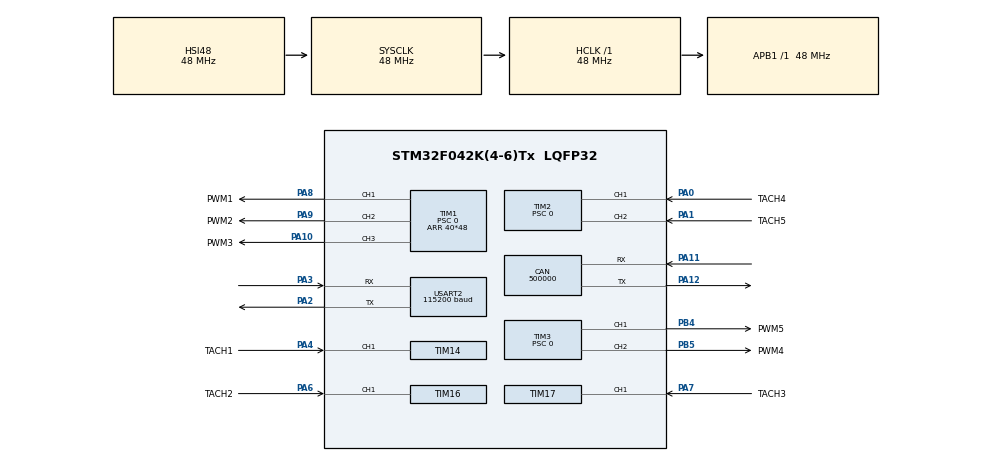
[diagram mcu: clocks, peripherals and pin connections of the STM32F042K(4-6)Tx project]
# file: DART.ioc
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CAN.BS1=CAN_BS1_4TQ
CAN.CalculateBaudRate=500000
CAN.CalculateTimeBit=2000
CAN.CalculateTimeQuantum=333.3333333333333
Dma.Request0=USART2_RX
Dma.Request1=USART2_TX
Dma.USART2_RX.0.Direction=DMA_PERIPH_TO_MEMORY
Dma.USART2_RX.0.Instance=DMA1_Channel5
Dma.USART2_RX.0.MemDataAlignment=DMA_MDATAALIGN_BYTE
Dma.USART2_RX.0.MemInc=DMA_MINC_ENABLE
Dma.USART2_RX.0.Mode=DMA_CIRCULAR
Dma.USART2_RX.0.PeriphDataAlignment=DMA_PDATAALIGN_BYTE
Dma.USART2_RX.0.PeriphInc=DMA_PINC_DISABLE
Dma.USART2_RX.0.Priority=DMA_PRIORITY_LOW
Dma.USART2_TX.1.Direction=DMA_MEMORY_TO_PERIPH
Dma.USART2_TX.1.Instance=DMA1_Channel4
Dma.USART2_TX.1.MemDataAlignment=DMA_MDATAALIGN_BYTE
Dma.USART2_TX.1.MemInc=DMA_MINC_ENABLE
Dma.USART2_TX.1.Mode=DMA_NORMAL
Dma.USART2_TX.1.PeriphDataAlignment=DMA_PDATAALIGN_BYTE
Dma.USART2_TX.1.PeriphInc=DMA_PINC_DISABLE
Dma.USART2_TX.1.Priority=DMA_PRIORITY_LOW
Mcu.Family=STM32F0
Mcu.Name=STM32F042K(4-6)Tx
Mcu.Package=LQFP32
NVIC.CEC_CAN_IRQn=true\:0\:0\:false\:false\:true\:true\:true\:true
NVIC.DMA1_Channel4_5_IRQn=true\:0\:0\:false\:false\:true\:false\:true\:true
NVIC.TIM14_IRQn=true\:0\:0\:false\:false\:true\:true\:true\:true
NVIC.TIM16_IRQn=true\:0\:0\:false\:false\:true\:true\:true\:true
NVIC.TIM17_IRQn=true\:0\:0\:false\:false\:true\:true\:true\:true
NVIC.TIM1_BRK_UP_TRG_COM_IRQn=true\:0\:0\:false\:false\:true\:true\:true\:true
NVIC.TIM1_CC_IRQn=true\:0\:0\:false\:false\:true\:true\:true\:true
NVIC.TIM2_IRQn=true\:0\:0\:false\:false\:true\:true\:true\:true
NVIC.TIM3_IRQn=true\:0\:0\:false\:false\:true\:true\:true\:true
NVIC.USART2_IRQn=true\:0\:0\:false\:false\:true\:true\:true\:true
PA0.GPIO_Label=TACH4
PA0.Signal=S_TIM2_CH1_ETR
PA1.GPIO_Label=TACH5
PA1.Signal=S_TIM2_CH2
PA10.GPIO_Label=PWM3
PA10.Signal=S_TIM1_CH3
PA11.Mode=CAN_Activate
PA11.Signal=CAN_RX
PA12.Mode=CAN_Activate
PA12.Signal=CAN_TX
PA13.Mode=Serial_Wire
PA13.Signal=SYS_SWDIO
PA14.Mode=Serial_Wire
PA14.Signal=SYS_SWCLK
PA2.Mode=Asynchronous
PA2.Signal=USART2_TX
PA3.Mode=Asynchronous
PA3.Signal=USART2_RX
PA4.GPIO_Label=TACH1
PA4.Signal=S_TIM14_CH1
PA6.GPIO_Label=TACH2
PA6.Signal=S_TIM16_CH1
PA7.GPIO_Label=TACH3
PA7.Signal=S_TIM17_CH1
PA8.GPIO_Label=PWM1
PA8.Signal=S_TIM1_CH1
PA9.GPIO_Label=PWM2
PA9.Signal=S_TIM1_CH2
PB4.GPIO_Label=PWM5
PB4.Signal=S_TIM3_CH1
PB5.GPIO_Label=PWM4
PB5.Signal=S_TIM3_CH2
ProjectManager.HeapSize=0x200
ProjectManager.StackSize=0x400
ProjectManager.TargetToolchain=CMake
RCC.AHBFreq_Value=48000000
RCC.APB1Freq_Value=48000000
RCC.APB1TimFreq_Value=48000000
RCC.HCLKFreq_Value=48000000
RCC.SYSCLKFreq_VALUE=48000000
RCC.SYSCLKSource=RCC_SYSCLKSOURCE_HSI48
SH.S_TIM14_CH1.0=TIM14_CH1,Input_Capture1_from_TI1
SH.S_TIM16_CH1.0=TIM16_CH1,Input_Capture1_from_TI1
SH.S_TIM17_CH1.0=TIM17_CH1,Input_Capture1_from_TI1
SH.S_TIM1_CH1.0=TIM1_CH1,PWM Generation1 CH1
SH.S_TIM1_CH2.0=TIM1_CH2,PWM Generation2 CH2
SH.S_TIM1_CH3.0=TIM1_CH3,PWM Generation3 CH3
SH.S_TIM2_CH1_ETR.0=TIM2_CH1,Input_Capture1_from_TI1
SH.S_TIM2_CH2.0=TIM2_CH2,Input_Capture2_from_TI2
SH.S_TIM3_CH1.0=TIM3_CH1,PWM Generation1 CH1
SH.S_TIM3_CH2.0=TIM3_CH2,PWM Generation2 CH2
TIM1.AutoReloadPreload=TIM_AUTORELOAD_PRELOAD_ENABLE
TIM1.Channel-PWM\ Generation1\ CH1=TIM_CHANNEL_1
TIM1.Channel-PWM\ Generation2\ CH2=TIM_CHANNEL_2
TIM1.Channel-PWM\ Generation3\ CH3=TIM_CHANNEL_3
TIM1.Period=40*48
TIM1.Prescaler=0
TIM14.AutoReloadPreload=TIM_AUTORELOAD_PRELOAD_ENABLE
TIM14.Channel=TIM_CHANNEL_1
TIM14.IC1Filter=15
TIM14.ICFilter_CH1=0xF
TIM14.Period=65535
TIM16.AutoReloadPreload=TIM_AUTORELOAD_PRELOAD_ENABLE
TIM16.Channel=TIM_CHANNEL_1
TIM16.IC1Filter=15
TIM16.ICFilter_CH1=0xF
TIM17.AutoReloadPreload=TIM_AUTORELOAD_PRELOAD_ENABLE
TIM17.Channel=TIM_CHANNEL_1
TIM17.IC1Filter=15
TIM17.ICFilter_CH1=0xF
TIM2.AutoReloadPreload=TIM_AUTORELOAD_PRELOAD_ENABLE
TIM2.Channel-Input_Capture1_from_TI1=TIM_CHANNEL_1
TIM2.Channel-Input_Capture2_from_TI2=TIM_CHANNEL_2
TIM2.IC1Filter=15
TIM2.IC2Filter=15
TIM2.ICFilter_CH1=0xF
TIM2.ICFilter_CH2=0xF
TIM2.Period=4294967295
TIM2.Prescaler=0
TIM3.AutoReloadPreload=TIM_AUTORELOAD_PRELOAD_ENABLE
TIM3.Channel-PWM\ Generation1\ CH1=TIM_CHANNEL_1
TIM3.Channel-PWM\ Generation2\ CH2=TIM_CHANNEL_2
TIM3.Period=40*48
TIM3.Prescaler=0
USART2.BaudRate=115200
USART2.VirtualMode-Asynchronous=VM_ASYNC
VP_TIM14_VS_ClockSourceINT.Mode=Enable_Timer
VP_TIM16_VS_ClockSourceINT.Mode=Enable_Timer
VP_TIM17_VS_ClockSourceINT.Mode=Enable_Timer
VP_TIM1_VS_ClockSourceINT.Mode=Internal
VP_TIM2_VS_ClockSourceINT.Mode=Internal
VP_TIM3_VS_ClockSourceINT.Mode=Internal
board=custom

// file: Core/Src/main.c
/* USER CODE BEGIN Header */
/**
 ******************************************************************************
 * @file           : main.c
 * @brief          : Main program body
 ******************************************************************************
 * @attention
 *
 * Copyright (c) 2024 STMicroelectronics.
 * All rights reserved.
 *
 * This software is licensed under terms that can be found in the LICENSE file
 * in the root directory of this software component.
 * If no LICENSE file comes with this software, it is provided AS-IS.
 *
 ******************************************************************************
 */
/* USER CODE END Header */
#include "main.h"
#include "can.h"
#include "dma.h"
#include "tim.h"
#include "usart.h"
#include "gpio.h"

/* USER CODE BEGIN PD */

// code for calculating frequency

/* USER CODE END PD */

void SystemClock_Config(void);

int main(void)
{

  /* MCU Configuration--------------------------------------------------------*/

  /* Reset of all peripherals, Initializes the Flash interface and the Systick. */
  HAL_Init();

  /* Configure the system clock */
  SystemClock_Config();

  /* Initialize all configured peripherals */
  MX_GPIO_Init();
  MX_DMA_Init();
  MX_TIM1_Init();
  MX_TIM2_Init();
  MX_USART2_UART_Init();
  MX_TIM3_Init();
  MX_CAN_Init();
  MX_TIM14_Init();
  MX_TIM16_Init();
  MX_TIM17_Init();
  /* USER CODE BEGIN 2 */

  // HAL_UART_Transmit(&huart2, (uint8_t *)"Hello World!\r\n", 15, 100);

  // HAL_GPIO_WritePin(PWM1_GPIO_Port, PWM1_Pin, GPIO_PIN_SET);
  // HAL_GPIO_WritePin(PWM2_GPIO_Port, PWM2_Pin, GPIO_PIN_SET);
  // HAL_GPIO_WritePin(PWM3_GPIO_Port, PWM3_Pin, GPIO_PIN_SET);
  // HAL_GPIO_WritePin(PWM4_GPIO_Port, PWM4_Pin, GPIO_PIN_SET);
  // HAL_GPIO_WritePin(PWM5_GPIO_Port, PWM5_Pin, GPIO_PIN_SET);

  FEB_Init();

  /* USER CODE END 2 */

  /* Infinite loop */
  /* USER CODE BEGIN WHILE */
  while (1)
  {
    FEB_Main_Loop();

    /* USER CODE END WHILE */

  }
}

void SystemClock_Config(void)
{
  RCC_OscInitTypeDef RCC_OscInitStruct = {0};
  RCC_ClkInitTypeDef RCC_ClkInitStruct = {0};

  /** Initializes the RCC Oscillators according to the specified parameters
   * in the RCC_OscInitTypeDef structure.
   */
  RCC_OscInitStruct.OscillatorType = RCC_OSCILLATORTYPE_HSI48;
  RCC_OscInitStruct.HSI48State = RCC_HSI48_ON;
  RCC_OscInitStruct.PLL.PLLState = RCC_PLL_NONE;
  if (HAL_RCC_OscConfig(&RCC_OscInitStruct) != HAL_OK)
  {
    Error_Handler();
  }

  /** Initializes the CPU, AHB and APB buses clocks
   */
  RCC_ClkInitStruct.ClockType = RCC_CLOCKTYPE_HCLK | RCC_CLOCKTYPE_SYSCLK | RCC_CLOCKTYPE_PCLK1;
  RCC_ClkInitStruct.SYSCLKSource = RCC_SYSCLKSOURCE_HSI48;
  RCC_ClkInitStruct.AHBCLKDivider = RCC_SYSCLK_DIV1;
  RCC_ClkInitStruct.APB1CLKDivider = RCC_HCLK_DIV1;

  if (HAL_RCC_ClockConfig(&RCC_ClkInitStruct, FLASH_LATENCY_1) != HAL_OK)
  {
    Error_Handler();
  }
  HAL_RCC_MCOConfig(RCC_MCO, RCC_MCO1SOURCE_SYSCLK, RCC_MCODIV_1);
}

/* USER CODE BEGIN 4 */
void HAL_TIM_IC_CaptureCallback(TIM_HandleTypeDef *htim)
{
  FEB_Fan_TACH_Callback(htim);
}
/* USER CODE END 4 */

void Error_Handler(void)
{
  __disable_irq();
  while (1)
  {
  }
}
